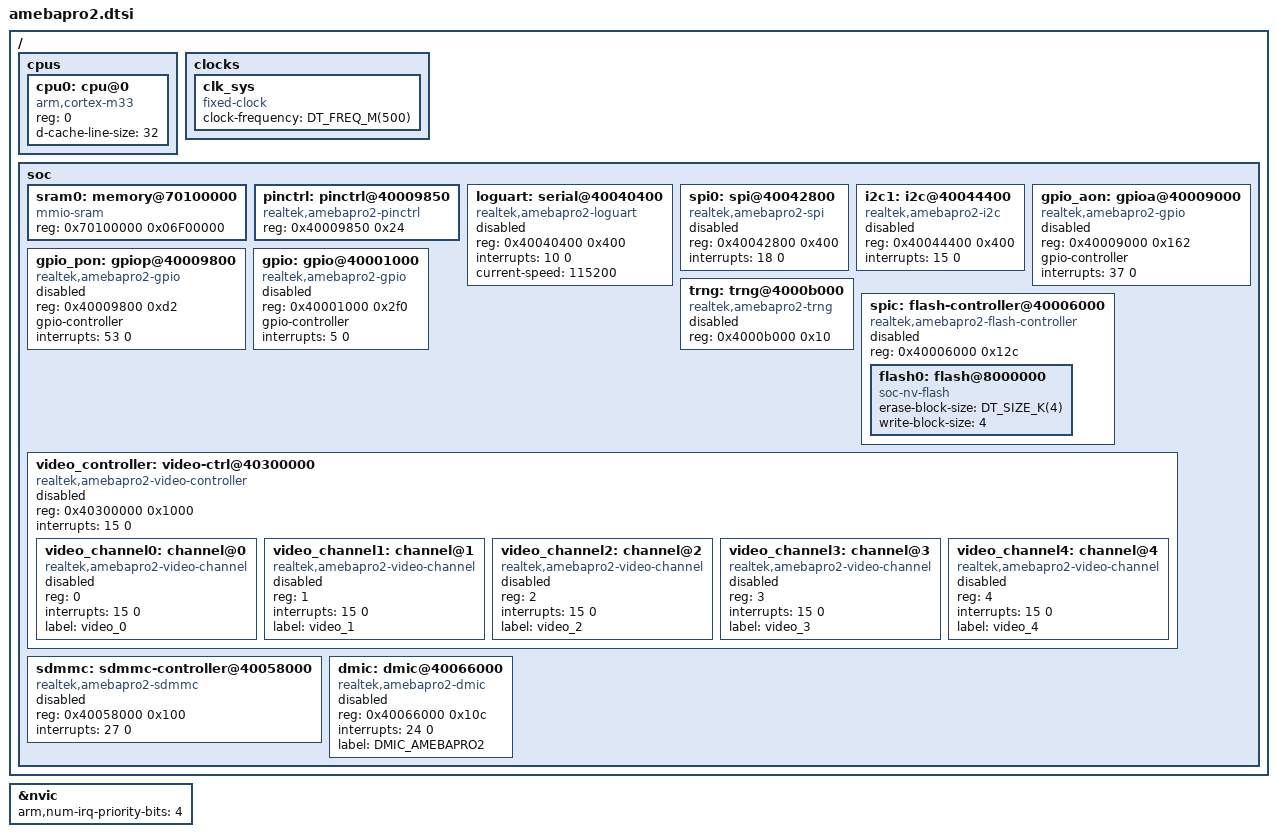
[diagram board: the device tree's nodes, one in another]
/*
 * Copyright (c) 2024 Realtek Semiconductor Corp.
 *
 * SPDX-License-Identifier: Apache-2.0
 */

#include <mem.h>
#include <freq.h>
#include <arm/armv8-m.dtsi>

/ {
	cpus {
		#address-cells = <1>;
		#size-cells = <0>;

		cpu0: cpu@0 {
			device_type = "cpu";
			compatible = "arm,cortex-m33";
			reg = <0>;
			d-cache-line-size = <32>;
			#address-cells = <1>;
			#size-cells = <1>;
		};
	};

	clocks {
		clk_sys: clk_sys {
			#clock-cells = <0>;
			compatible = "fixed-clock";
			clock-frequency = <DT_FREQ_M(500)>;
		};
	};

	soc {
		sram0: memory@70100000 {
			compatible = "mmio-sram";
			reg = <0x70100000 0x06F00000>;
		};

		pinctrl: pinctrl@40009850 {
			compatible = "realtek,amebapro2-pinctrl";
			reg = <0x40009850 0x24>;
		};

		loguart: serial@40040400 {
			compatible = "realtek,amebapro2-loguart";
			reg = <0x40040400 0x400>;
			interrupts = <10 0>;
			current-speed = <115200>;
			status = "disabled";
		};

		spi0: spi@40042800 {
			compatible = "realtek,amebapro2-spi";
			reg = <0x40042800 0x400>;
			interrupts = <18 0>;
			#address-cells = <1>;
			#size-cells = <0>;
			status = "disabled";
		};

		i2c1: i2c@40044400 {
			compatible = "realtek,amebapro2-i2c";
			reg = <0x40044400 0x400>;
			interrupts = <15 0>;
			#address-cells = <1>;
			#size-cells = <0>;
			status = "disabled";
		};

		gpio_aon: gpioa@40009000 {
			compatible = "realtek,amebapro2-gpio";
			reg = <0x40009000 0x162>;
			gpio-controller;
			#gpio-cells = <2>;
			interrupts = <37 0>;
			status = "disabled";
		};

		gpio_pon: gpiop@40009800 {
			compatible = "realtek,amebapro2-gpio";
			reg = <0x40009800 0xd2>;
			gpio-controller;
			#gpio-cells = <2>;
			interrupts = <53 0>;
			status = "disabled";
		};

		gpio: gpio@40001000 {
			compatible = "realtek,amebapro2-gpio";
			reg = <0x40001000 0x2f0>;
			gpio-controller;
			#gpio-cells = <2>;
			interrupts = <5 0>;
			status = "disabled";
		};

		trng: trng@4000b000 {
			compatible = "realtek,amebapro2-trng";
			reg = <0x4000b000 0x10>;
			status = "disabled";
		};

		spic: flash-controller@40006000 {
			compatible = "realtek,amebapro2-flash-controller";
			reg = <0x40006000 0x12c>;

			#address-cells = <1>;
			#size-cells = <1>;
			status = "disabled";

			flash0: flash@8000000 {
				compatible = "soc-nv-flash";
				erase-block-size = <DT_SIZE_K(4)>;
				write-block-size = <4>;
				/* Flash size is specified in board dts */
			};
		};

		video_controller: video-ctrl@40300000 {
			compatible = "realtek,amebapro2-video-controller";
			reg = <0x40300000 0x1000>;
			interrupts = <15 0>;
			status = "disabled";

			#address-cells = <1>;
			#size-cells = <0>;

			video_channel0: channel@0 {
				compatible = "realtek,amebapro2-video-channel";
				reg = <0>;
				interrupts = <15 0>;
				label = "video_0";
				status = "disabled";
			};

			video_channel1: channel@1 {
				compatible = "realtek,amebapro2-video-channel";
				reg = <1>;
				interrupts = <15 0>;
				label = "video_1";
				status = "disabled";
			};

			video_channel2: channel@2 {
				compatible = "realtek,amebapro2-video-channel";
				reg = <2>;
				interrupts = <15 0>;
				label = "video_2";
				status = "disabled";
			};

			video_channel3: channel@3 {
				compatible = "realtek,amebapro2-video-channel";
				reg = <3>;
				interrupts = <15 0>;
				label = "video_3";
				status = "disabled";
			};

			video_channel4: channel@4 {
				compatible = "realtek,amebapro2-video-channel";
				reg = <4>;
				interrupts = <15 0>;
				label = "video_4";
				status = "disabled";
			};
		};

		sdmmc: sdmmc-controller@40058000 {
			compatible = "realtek,amebapro2-sdmmc";
			reg = <0x40058000 0x100>;
			interrupts = <27 0>;
			status = "disabled";
		};

		dmic: dmic@40066000 {
			compatible = "realtek,amebapro2-dmic";
			reg = <0x40066000 0x10c>;
			interrupts = <24 0>;
			status = "disabled";
			label = "DMIC_AMEBAPRO2";
		};
	};
};

&nvic {
	arm,num-irq-priority-bits = <4>;
};
